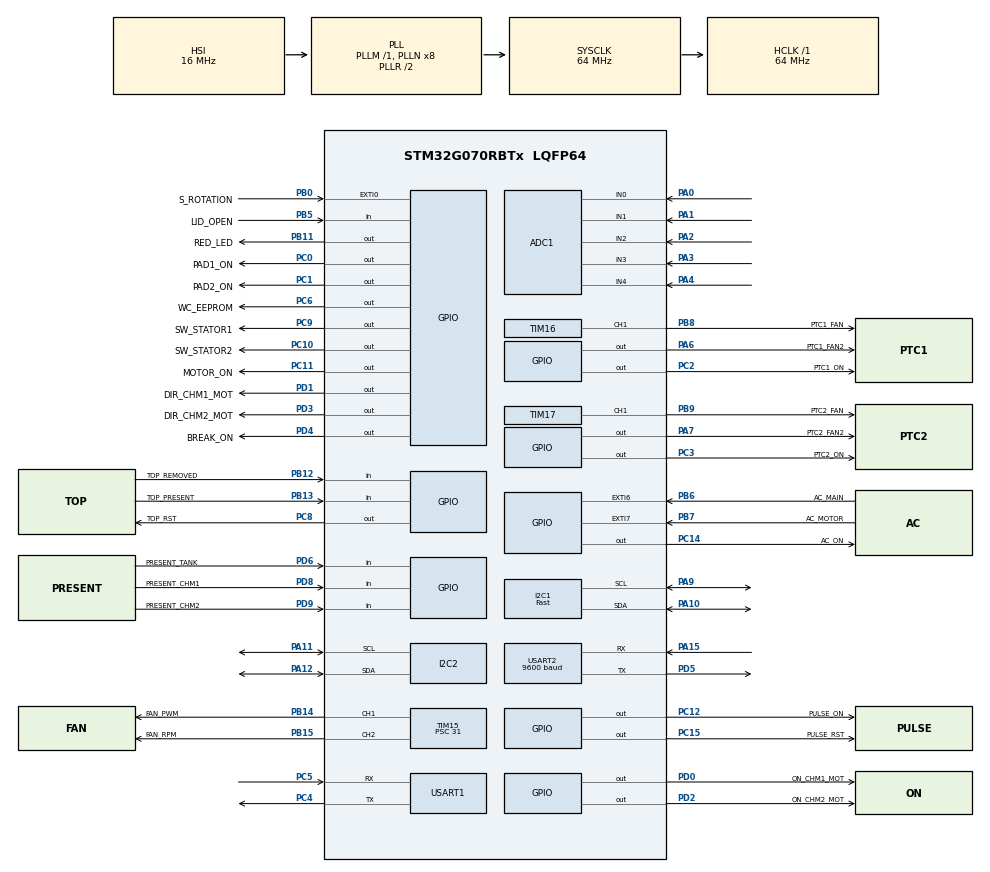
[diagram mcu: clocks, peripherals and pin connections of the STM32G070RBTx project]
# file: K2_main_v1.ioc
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ADC1.Channel-0\#ChannelRegularConversion=ADC_CHANNEL_0
ADC1.Channel-1\#ChannelRegularConversion=ADC_CHANNEL_1
ADC1.Channel-2\#ChannelRegularConversion=ADC_CHANNEL_2
ADC1.Channel-3\#ChannelRegularConversion=ADC_CHANNEL_3
ADC1.Channel-4\#ChannelRegularConversion=ADC_CHANNEL_4
ADC1.Channel-5\#ChannelRegularConversion=ADC_CHANNEL_TEMPSENSOR
ADC1.Channel-6\#ChannelRegularConversion=ADC_CHANNEL_VREFINT
ADC1.Channel-7\#ChannelRegularConversion=ADC_CHANNEL_VBAT
ADC1.EOCSelection=ADC_EOC_SEQ_CONV
ADC1.NbrOfConversion=8
ADC1.NbrOfConversionFlag=1
ADC1.Rank-0\#ChannelRegularConversion=1
ADC1.Rank-1\#ChannelRegularConversion=2
ADC1.Rank-2\#ChannelRegularConversion=3
ADC1.Rank-3\#ChannelRegularConversion=4
ADC1.Rank-4\#ChannelRegularConversion=5
ADC1.Rank-5\#ChannelRegularConversion=6
ADC1.Rank-6\#ChannelRegularConversion=7
ADC1.Rank-7\#ChannelRegularConversion=8
ADC1.SamplingTime-0\#ChannelRegularConversion=ADC_SAMPLINGTIME_COMMON_1
ADC1.SamplingTime-1\#ChannelRegularConversion=ADC_SAMPLINGTIME_COMMON_1
ADC1.SamplingTime-2\#ChannelRegularConversion=ADC_SAMPLINGTIME_COMMON_1
ADC1.SamplingTime-3\#ChannelRegularConversion=ADC_SAMPLINGTIME_COMMON_1
ADC1.SamplingTime-4\#ChannelRegularConversion=ADC_SAMPLINGTIME_COMMON_1
ADC1.SamplingTime-5\#ChannelRegularConversion=ADC_SAMPLINGTIME_COMMON_1
ADC1.SamplingTime-6\#ChannelRegularConversion=ADC_SAMPLINGTIME_COMMON_1
ADC1.SamplingTime-7\#ChannelRegularConversion=ADC_SAMPLINGTIME_COMMON_1
ADC1.SamplingTimeCommon1=ADC_SAMPLETIME_3CYCLES_5
ADC1.SelectedChannel=ADC_CHANNEL_0|ADC_CHANNEL_1|ADC_CHANNEL_2|ADC_CHANNEL_3|ADC_CHANNEL_4|ADC_CHANNEL_TEMPSENSOR|ADC_CHANNEL_VREFINT|ADC_CHANNEL_VBAT
ADC1.master=1
Dma.ADC1.0.Direction=DMA_PERIPH_TO_MEMORY
Dma.ADC1.0.EventEnable=DISABLE
Dma.ADC1.0.Instance=DMA1_Channel1
Dma.ADC1.0.MemDataAlignment=DMA_MDATAALIGN_HALFWORD
Dma.ADC1.0.MemInc=DMA_MINC_ENABLE
Dma.ADC1.0.Mode=DMA_NORMAL
Dma.ADC1.0.PeriphDataAlignment=DMA_PDATAALIGN_HALFWORD
Dma.ADC1.0.PeriphInc=DMA_PINC_DISABLE
Dma.ADC1.0.Polarity=HAL_DMAMUX_REQ_GEN_RISING
Dma.ADC1.0.Priority=DMA_PRIORITY_LOW
Dma.ADC1.0.RequestNumber=1
Dma.ADC1.0.SignalID=NONE
Dma.ADC1.0.SyncEnable=DISABLE
Dma.ADC1.0.SyncPolarity=HAL_DMAMUX_SYNC_NO_EVENT
Dma.ADC1.0.SyncRequestNumber=1
Dma.ADC1.0.SyncSignalID=NONE
Dma.Request0=ADC1
Dma.Request1=USART1_RX
Dma.Request2=USART1_TX
Dma.Request3=USART2_RX
Dma.Request4=USART2_TX
Dma.USART1_RX.1.Direction=DMA_PERIPH_TO_MEMORY
Dma.USART1_RX.1.EventEnable=DISABLE
Dma.USART1_RX.1.Instance=DMA1_Channel2
Dma.USART1_RX.1.MemDataAlignment=DMA_MDATAALIGN_BYTE
Dma.USART1_RX.1.MemInc=DMA_MINC_ENABLE
Dma.USART1_RX.1.Mode=DMA_NORMAL
Dma.USART1_RX.1.PeriphDataAlignment=DMA_PDATAALIGN_BYTE
Dma.USART1_RX.1.PeriphInc=DMA_PINC_DISABLE
Dma.USART1_RX.1.Polarity=HAL_DMAMUX_REQ_GEN_RISING
Dma.USART1_RX.1.Priority=DMA_PRIORITY_LOW
Dma.USART1_RX.1.RequestNumber=1
Dma.USART1_RX.1.SignalID=NONE
Dma.USART1_RX.1.SyncEnable=DISABLE
Dma.USART1_RX.1.SyncPolarity=HAL_DMAMUX_SYNC_NO_EVENT
Dma.USART1_RX.1.SyncRequestNumber=1
Dma.USART1_RX.1.SyncSignalID=NONE
Dma.USART1_TX.2.Direction=DMA_MEMORY_TO_PERIPH
Dma.USART1_TX.2.EventEnable=DISABLE
Dma.USART1_TX.2.Instance=DMA1_Channel3
Dma.USART1_TX.2.MemDataAlignment=DMA_MDATAALIGN_BYTE
Dma.USART1_TX.2.MemInc=DMA_MINC_ENABLE
Dma.USART1_TX.2.Mode=DMA_NORMAL
Dma.USART1_TX.2.PeriphDataAlignment=DMA_PDATAALIGN_BYTE
Dma.USART1_TX.2.PeriphInc=DMA_PINC_DISABLE
Dma.USART1_TX.2.Polarity=HAL_DMAMUX_REQ_GEN_RISING
Dma.USART1_TX.2.Priority=DMA_PRIORITY_LOW
Dma.USART1_TX.2.RequestNumber=1
Dma.USART1_TX.2.SignalID=NONE
Dma.USART1_TX.2.SyncEnable=DISABLE
Dma.USART1_TX.2.SyncPolarity=HAL_DMAMUX_SYNC_NO_EVENT
Dma.USART1_TX.2.SyncRequestNumber=1
Dma.USART1_TX.2.SyncSignalID=NONE
Dma.USART2_RX.3.Direction=DMA_PERIPH_TO_MEMORY
Dma.USART2_RX.3.EventEnable=DISABLE
Dma.USART2_RX.3.Instance=DMA1_Channel4
Dma.USART2_RX.3.MemDataAlignment=DMA_MDATAALIGN_BYTE
Dma.USART2_RX.3.MemInc=DMA_MINC_ENABLE
Dma.USART2_RX.3.Mode=DMA_NORMAL
Dma.USART2_RX.3.PeriphDataAlignment=DMA_PDATAALIGN_BYTE
Dma.USART2_RX.3.PeriphInc=DMA_PINC_DISABLE
Dma.USART2_RX.3.Polarity=HAL_DMAMUX_REQ_GEN_RISING
Dma.USART2_RX.3.Priority=DMA_PRIORITY_LOW
Dma.USART2_RX.3.RequestNumber=1
Dma.USART2_RX.3.SignalID=NONE
Dma.USART2_RX.3.SyncEnable=DISABLE
Dma.USART2_RX.3.SyncPolarity=HAL_DMAMUX_SYNC_NO_EVENT
Dma.USART2_RX.3.SyncRequestNumber=1
Dma.USART2_RX.3.SyncSignalID=NONE
Dma.USART2_TX.4.Direction=DMA_MEMORY_TO_PERIPH
Dma.USART2_TX.4.EventEnable=DISABLE
Dma.USART2_TX.4.Instance=DMA1_Channel5
Dma.USART2_TX.4.MemDataAlignment=DMA_MDATAALIGN_BYTE
Dma.USART2_TX.4.MemInc=DMA_MINC_ENABLE
Dma.USART2_TX.4.Mode=DMA_NORMAL
Dma.USART2_TX.4.PeriphDataAlignment=DMA_PDATAALIGN_BYTE
Dma.USART2_TX.4.PeriphInc=DMA_PINC_DISABLE
Dma.USART2_TX.4.Polarity=HAL_DMAMUX_REQ_GEN_RISING
Dma.USART2_TX.4.Priority=DMA_PRIORITY_LOW
Dma.USART2_TX.4.RequestNumber=1
Dma.USART2_TX.4.SignalID=NONE
Dma.USART2_TX.4.SyncEnable=DISABLE
Dma.USART2_TX.4.SyncPolarity=HAL_DMAMUX_SYNC_NO_EVENT
Dma.USART2_TX.4.SyncRequestNumber=1
Dma.USART2_TX.4.SyncSignalID=NONE
FREERTOS.INCLUDE_xEventGroupSetBitFromISR=1
FREERTOS.INCLUDE_xTimerPendFunctionCall=1
FREERTOS.MEMORY_ALLOCATION=2
FREERTOS.Tasks01=defaultTask,0,64,StartDefaultTask,Default,NULL,Static,defaultTaskBuffer,defaultTaskControlBlock
FREERTOS.configMAX_PRIORITIES=10
FREERTOS.configMAX_TASK_NAME_LEN=32
FREERTOS.configMINIMAL_STACK_SIZE=64
FREERTOS.configTOTAL_HEAP_SIZE=1024
FREERTOS.configUSE_NEWLIB_REENTRANT=1
FREERTOS.configUSE_TICK_HOOK=1
FREERTOS.configUSE_TIMERS=1
I2C1.I2C_Speed_Mode=I2C_Fast
I2C1.Timing=0x00602173
I2C2.Timing=0x10707DBC
Mcu.Family=STM32G0
Mcu.Name=STM32G070RBTx
Mcu.Package=LQFP64
NVIC.DMA1_Ch4_7_DMAMUX1_OVR_IRQn=true\:3\:0\:false\:false\:true\:true\:false\:true\:true
NVIC.DMA1_Channel1_IRQn=true\:3\:0\:false\:false\:true\:true\:false\:true\:true
NVIC.DMA1_Channel2_3_IRQn=true\:3\:0\:false\:false\:true\:true\:false\:true\:true
NVIC.EXTI4_15_IRQn=true\:3\:0\:false\:false\:true\:true\:true\:true\:true
NVIC.USART1_IRQn=true\:3\:0\:false\:false\:true\:true\:true\:true\:true
NVIC.USART2_IRQn=true\:3\:0\:false\:false\:true\:true\:true\:true\:true
PA0.Mode=IN0
PA0.Signal=ADC1_IN0
PA1.Mode=IN1
PA1.Signal=ADC1_IN1
PA10.Mode=I2C
PA10.Signal=I2C1_SDA
PA11\ [PA9].Mode=I2C
PA11\ [PA9].Signal=I2C2_SCL
PA12\ [PA10].Mode=I2C
PA12\ [PA10].Signal=I2C2_SDA
PA13.Mode=Serial_Wire
PA13.Signal=SYS_SWDIO
PA14-BOOT0.Mode=Serial_Wire
PA14-BOOT0.Signal=SYS_SWCLK
PA15.GPIO_PuPd=GPIO_NOPULL
PA15.Mode=Asynchronous
PA15.Signal=USART2_RX
PA2.Mode=IN2
PA2.Signal=ADC1_IN2
PA3.Mode=IN3
PA3.Signal=ADC1_IN3
PA4.Mode=IN4
PA4.Signal=ADC1_IN4
PA6.GPIO_Label=PTC1_FAN2
PA6.GPIO_ModeDefaultOutputPP=GPIO_MODE_OUTPUT_OD
PA6.GPIO_PuPd=GPIO_NOPULL
PA6.PinState=GPIO_PIN_SET
PA6.Signal=GPIO_Output
PA7.GPIO_Label=PTC2_FAN2
PA7.GPIO_ModeDefaultOutputPP=GPIO_MODE_OUTPUT_OD
PA7.GPIO_PuPd=GPIO_NOPULL
PA7.PinState=GPIO_PIN_SET
PA7.Signal=GPIO_Output
PA9.Mode=I2C
PA9.Signal=I2C1_SCL
PB0.GPIO_Label=S_ROTATION
PB0.Signal=GPXTI0
PB11.GPIO_Label=RED_LED
PB11.GPIO_ModeDefaultOutputPP=GPIO_MODE_OUTPUT_OD
PB11.GPIO_PuPd=GPIO_NOPULL
PB11.PinState=GPIO_PIN_SET
PB11.Signal=GPIO_Output
PB12.GPIO_Label=TOP_REMOVED
PB12.Signal=GPIO_Input
PB13.GPIO_Label=TOP_PRESENT
PB13.Signal=GPIO_Input
PB14.GPIO_Label=FAN_PWM
PB14.Signal=S_TIM15_CH1
PB15.GPIO_Label=FAN_RPM
PB15.Signal=S_TIM15_CH2
PB5.GPIO_Label=LID_OPEN
PB5.Signal=GPIO_Input
PB6.GPIO_Label=AC_MAIN
PB6.GPIO_ModeDefaultEXTI=GPIO_MODE_IT_FALLING
PB6.Signal=GPXTI6
PB7.GPIO_Label=AC_MOTOR
PB7.GPIO_ModeDefaultEXTI=GPIO_MODE_IT_FALLING
PB7.Signal=GPXTI7
PB8.GPIO_Label=PTC1_FAN
PB8.Signal=S_TIM16_CH1
PB9.GPIO_Label=PTC2_FAN
PB9.Signal=S_TIM17_CH1
PC0.GPIO_Label=PAD1_ON
PC0.GPIO_ModeDefaultOutputPP=GPIO_MODE_OUTPUT_OD
PC0.GPIO_PuPd=GPIO_NOPULL
PC0.PinState=GPIO_PIN_SET
PC0.Signal=GPIO_Output
PC1.GPIO_Label=PAD2_ON
PC1.GPIO_ModeDefaultOutputPP=GPIO_MODE_OUTPUT_OD
PC1.GPIO_PuPd=GPIO_NOPULL
PC1.PinState=GPIO_PIN_SET
PC1.Signal=GPIO_Output
PC10.GPIO_Label=SW_STATOR2
PC10.Signal=GPIO_Output
PC11.GPIO_Label=MOTOR_ON
PC11.GPIO_ModeDefaultOutputPP=GPIO_MODE_OUTPUT_OD
PC11.GPIO_PuPd=GPIO_PULLUP
PC11.Signal=GPIO_Output
PC12.GPIO_Label=PULSE_ON
PC12.GPIO_ModeDefaultOutputPP=GPIO_MODE_OUTPUT_OD
PC12.GPIO_PuPd=GPIO_NOPULL
PC12.PinState=GPIO_PIN_SET
PC12.Signal=GPIO_Output
PC13.Mode=SYS_WakeUp1
PC13.Signal=SYS_WKUP2
PC14-OSC32_IN\ (PC14).GPIO_Label=AC_ON
PC14-OSC32_IN\ (PC14).Signal=GPIO_Output
PC15-OSC32_OUT\ (PC15).GPIO_Label=PULSE_RST
PC15-OSC32_OUT\ (PC15).Signal=GPIO_Output
PC2.GPIO_Label=PTC1_ON
PC2.GPIO_ModeDefaultOutputPP=GPIO_MODE_OUTPUT_OD
PC2.GPIO_PuPd=GPIO_NOPULL
PC2.PinState=GPIO_PIN_SET
PC2.Signal=GPIO_Output
PC3.GPIO_Label=PTC2_ON
PC3.GPIO_ModeDefaultOutputPP=GPIO_MODE_OUTPUT_OD
PC3.GPIO_PuPd=GPIO_NOPULL
PC3.PinState=GPIO_PIN_SET
PC3.Signal=GPIO_Output
PC4.GPIO_PuPd=GPIO_PULLUP
PC4.Mode=Asynchronous
PC4.Signal=USART1_TX
PC5.GPIO_PuPd=GPIO_PULLUP
PC5.Mode=Asynchronous
PC5.Signal=USART1_RX
PC6.GPIO_Label=WC_EEPROM
PC6.GPIO_PuPd=GPIO_NOPULL
PC6.PinState=GPIO_PIN_SET
PC6.Signal=GPIO_Output
PC8.GPIO_Label=TOP_RST
PC8.Signal=GPIO_Output
PC9.GPIO_Label=SW_STATOR1
PC9.Signal=GPIO_Output
PD0.GPIO_Label=ON_CHM1_MOT
PD0.Signal=GPIO_Output
PD1.GPIO_Label=DIR_CHM1_MOT
PD1.Signal=GPIO_Output
PD2.GPIO_Label=ON_CHM2_MOT
PD2.Signal=GPIO_Output
PD3.GPIO_Label=DIR_CHM2_MOT
PD3.Signal=GPIO_Output
PD4.GPIO_Label=BREAK_ON
PD4.Signal=GPIO_Output
PD5.Mode=Asynchronous
PD5.Signal=USART2_TX
PD6.GPIO_Label=PRESENT_TANK
PD6.Signal=GPIO_Input
PD8.GPIO_Label=PRESENT_CHM1
PD8.Signal=GPIO_Input
PD9.GPIO_Label=PRESENT_CHM2
PD9.Signal=GPIO_Input
ProjectManager.HeapSize=0x200
ProjectManager.StackSize=0x400
ProjectManager.TargetToolchain=STM32CubeIDE
RCC.ADCFreq_Value=64000000
RCC.AHBFreq_Value=64000000
RCC.CortexFreq_Value=64000000
RCC.EXTERNAL_CLOCK_VALUE=48000
RCC.HCLKFreq_Value=64000000
RCC.HSE_VALUE=8000000
RCC.HSI_VALUE=16000000
RCC.LSE_VALUE=32768
RCC.SYSCLKFreq_VALUE=64000000
RCC.SYSCLKSource=RCC_SYSCLKSOURCE_PLLCLK
RCC.VCOOutputFreq_Value=128000000
SH.S_TIM15_CH1.0=TIM15_CH1,PWM Generation1 CH1
SH.S_TIM15_CH2.0=TIM15_CH2,PWM Generation2 CH2
SH.S_TIM16_CH1.0=TIM16_CH1,PWM Generation1 CH1
SH.S_TIM17_CH1.0=TIM17_CH1,PWM Generation1 CH1
TIM15.AutoReloadPreload=TIM_AUTORELOAD_PRELOAD_ENABLE
TIM15.Channel-PWM\ Generation1\ CH1=TIM_CHANNEL_1
TIM15.Channel-PWM\ Generation2\ CH2=TIM_CHANNEL_2
TIM15.Period=99
TIM15.Prescaler=31
TIM16.AutoReloadPreload=TIM_AUTORELOAD_PRELOAD_ENABLE
TIM16.Channel=TIM_CHANNEL_1
TIM16.OCIdleState_1=TIM_OCIDLESTATE_RESET
TIM16.OCPolarity_1=TIM_OCPOLARITY_HIGH
TIM16.Period=99
TIM16.Prescaler=31
TIM17.AutoReloadPreload=TIM_AUTORELOAD_PRELOAD_ENABLE
TIM17.Channel=TIM_CHANNEL_1
TIM17.Period=99
TIM17.Prescaler=31
USART1.VirtualMode-Asynchronous=VM_ASYNC
USART2.BaudRate=9600
USART2.TxPinLevelInvertParam=ADVFEATURE_TXINV_ENABLE
USART2.VirtualMode-Asynchronous=VM_ASYNC
VP_ADC1_TempSens_Input.Mode=IN-TempSens
VP_ADC1_Vbat_Input.Mode=IN-Vbat
VP_ADC1_Vref_Input.Mode=IN-Vrefint
VP_FREERTOS_VS_CMSIS_V1.Mode=CMSIS_V1
VP_TIM15_VS_ClockSourceINT.Mode=Internal
VP_TIM16_VS_ClockSourceINT.Mode=Enable_Timer
VP_TIM17_VS_ClockSourceINT.Mode=Enable_Timer
board=custom

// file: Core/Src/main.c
/* USER CODE BEGIN Header */
/**
  ******************************************************************************
  * @file           : main.c
  * @brief          : Main program body
  ******************************************************************************
  * @attention
  *
  * Copyright (c) 2023 STMicroelectronics.
  * All rights reserved.
  *
  * This software is licensed under terms that can be found in the LICENSE file
  * in the root directory of this software component.
  * If no LICENSE file comes with this software, it is provided AS-IS.
  *
  ******************************************************************************
  */
/* USER CODE END Header */
#include "main.h"
#include "cmsis_os.h"

/* USER CODE BEGIN Includes */
#include "ConfigApplication.h"
/* USER CODE END Includes */

ADC_HandleTypeDef hadc1;
DMA_HandleTypeDef hdma_adc1;

I2C_HandleTypeDef hi2c1;
I2C_HandleTypeDef hi2c2;

TIM_HandleTypeDef htim15;
TIM_HandleTypeDef htim16;
TIM_HandleTypeDef htim17;

UART_HandleTypeDef huart1;
UART_HandleTypeDef huart2;
DMA_HandleTypeDef hdma_usart1_rx;
DMA_HandleTypeDef hdma_usart1_tx;
DMA_HandleTypeDef hdma_usart2_rx;
DMA_HandleTypeDef hdma_usart2_tx;

/* osThreadId defaultTaskHandle;
uint32_t defaultTaskBuffer[ 64 ];
osStaticThreadDef_t defaultTaskControlBlock; */

void SystemClock_Config(void);
static void MX_GPIO_Init(void);
static void MX_DMA_Init(void);
static void MX_ADC1_Init(void);
static void MX_I2C1_Init(void);
static void MX_USART1_UART_Init(void);
static void MX_USART2_UART_Init(void);
static void MX_TIM16_Init(void);
static void MX_TIM15_Init(void);
static void MX_I2C2_Init(void);
static void MX_TIM17_Init(void);
// void StartDefaultTask(void const * argument);

/* USER CODE BEGIN PFP */
extern void CreateApplicationTasks(void);
/* USER CODE END PFP */

int main(void)
{

  /* MCU Configuration--------------------------------------------------------*/

  /* Reset of all peripherals, Initializes the Flash interface and the Systick. */
  HAL_Init();

  /* Configure the system clock */
  SystemClock_Config();

  /* Initialize all configured peripherals */
  MX_GPIO_Init();
  MX_DMA_Init();
  MX_ADC1_Init();
  MX_I2C1_Init();
  MX_USART1_UART_Init();
  MX_USART2_UART_Init();
  MX_TIM16_Init();
  MX_TIM15_Init();
  MX_I2C2_Init();
  MX_TIM17_Init();

  /* Create the thread(s) */
  /* definition and creation of defaultTask */
  // osThreadStaticDef(defaultTask, StartDefaultTask, osPriorityNormal, 0, 64, defaultTaskBuffer, &defaultTaskControlBlock);
  // defaultTaskHandle = osThreadCreate(osThread(defaultTask), NULL);

  /* USER CODE BEGIN RTOS_THREADS */
  /* add threads, ... */
  CreateApplicationTasks();
  /* USER CODE END RTOS_THREADS */

  /* Start scheduler */
  osKernelStart();
  /* We should never get here as control is now taken by the scheduler */
  /* Infinite loop */
  while (1)
  {

  }
}

void SystemClock_Config(void)
{
  RCC_OscInitTypeDef RCC_OscInitStruct = {0};
  RCC_ClkInitTypeDef RCC_ClkInitStruct = {0};

  /** Configure the main internal regulator output voltage
  */
  HAL_PWREx_ControlVoltageScaling(PWR_REGULATOR_VOLTAGE_SCALE1);

  /** Initializes the RCC Oscillators according to the specified parameters
  * in the RCC_OscInitTypeDef structure.
  */
  RCC_OscInitStruct.OscillatorType = RCC_OSCILLATORTYPE_HSI;
  RCC_OscInitStruct.HSIState = RCC_HSI_ON;
  RCC_OscInitStruct.HSIDiv = RCC_HSI_DIV1;
  RCC_OscInitStruct.HSICalibrationValue = RCC_HSICALIBRATION_DEFAULT;
  RCC_OscInitStruct.PLL.PLLState = RCC_PLL_ON;
  RCC_OscInitStruct.PLL.PLLSource = RCC_PLLSOURCE_HSI;
  RCC_OscInitStruct.PLL.PLLM = RCC_PLLM_DIV1;
  RCC_OscInitStruct.PLL.PLLN = 8;
  RCC_OscInitStruct.PLL.PLLP = RCC_PLLP_DIV2;
  RCC_OscInitStruct.PLL.PLLR = RCC_PLLR_DIV2;
  if (HAL_RCC_OscConfig(&RCC_OscInitStruct) != HAL_OK)
  {
    Error_Handler();
  }

  /** Initializes the CPU, AHB and APB buses clocks
  */
  RCC_ClkInitStruct.ClockType = RCC_CLOCKTYPE_HCLK|RCC_CLOCKTYPE_SYSCLK
                              |RCC_CLOCKTYPE_PCLK1;
  RCC_ClkInitStruct.SYSCLKSource = RCC_SYSCLKSOURCE_PLLCLK;
  RCC_ClkInitStruct.AHBCLKDivider = RCC_SYSCLK_DIV1;
  RCC_ClkInitStruct.APB1CLKDivider = RCC_HCLK_DIV1;

  if (HAL_RCC_ClockConfig(&RCC_ClkInitStruct, FLASH_LATENCY_2) != HAL_OK)
  {
    Error_Handler();
  }
}

static void MX_ADC1_Init(void)
{

  ADC_ChannelConfTypeDef sConfig = {0};

  /** Configure the global features of the ADC (Clock, Resolution, Data Alignment and number of conversion)
  */
  hadc1.Instance = ADC1;
  hadc1.Init.ClockPrescaler = ADC_CLOCK_SYNC_PCLK_DIV2;
  hadc1.Init.Resolution = ADC_RESOLUTION_12B;
  hadc1.Init.DataAlign = ADC_DATAALIGN_RIGHT;
  hadc1.Init.ScanConvMode = ADC_SCAN_ENABLE;
  hadc1.Init.EOCSelection = ADC_EOC_SEQ_CONV;
  hadc1.Init.LowPowerAutoWait = DISABLE;
  hadc1.Init.LowPowerAutoPowerOff = DISABLE;
  hadc1.Init.ContinuousConvMode = DISABLE;
  hadc1.Init.NbrOfConversion = 8;
  hadc1.Init.DiscontinuousConvMode = DISABLE;
  hadc1.Init.ExternalTrigConv = ADC_SOFTWARE_START;
  hadc1.Init.ExternalTrigConvEdge = ADC_EXTERNALTRIGCONVEDGE_NONE;
  hadc1.Init.DMAContinuousRequests = DISABLE;
  hadc1.Init.Overrun = ADC_OVR_DATA_PRESERVED;
  hadc1.Init.SamplingTimeCommon1 = ADC_SAMPLETIME_3CYCLES_5;
  hadc1.Init.SamplingTimeCommon2 = ADC_SAMPLETIME_1CYCLE_5;
  hadc1.Init.OversamplingMode = DISABLE;
  hadc1.Init.TriggerFrequencyMode = ADC_TRIGGER_FREQ_HIGH;
  if (HAL_ADC_Init(&hadc1) != HAL_OK)
  {
    Error_Handler();
  }

  /** Configure Regular Channel
  */
  sConfig.Channel = ADC_CHANNEL_0;
  sConfig.Rank = ADC_REGULAR_RANK_1;
  sConfig.SamplingTime = ADC_SAMPLINGTIME_COMMON_1;
  if (HAL_ADC_ConfigChannel(&hadc1, &sConfig) != HAL_OK)
  {
    Error_Handler();
  }

  /** Configure Regular Channel
  */
  sConfig.Channel = ADC_CHANNEL_1;
  sConfig.Rank = ADC_REGULAR_RANK_2;
  if (HAL_ADC_ConfigChannel(&hadc1, &sConfig) != HAL_OK)
  {
    Error_Handler();
  }

  /** Configure Regular Channel
  */
  sConfig.Channel = ADC_CHANNEL_2;
  sConfig.Rank = ADC_REGULAR_RANK_3;
  if (HAL_ADC_ConfigChannel(&hadc1, &sConfig) != HAL_OK)
  {
    Error_Handler();
  }

  /** Configure Regular Channel
  */
  sConfig.Channel = ADC_CHANNEL_3;
  sConfig.Rank = ADC_REGULAR_RANK_4;
  if (HAL_ADC_ConfigChannel(&hadc1, &sConfig) != HAL_OK)
  {
    Error_Handler();
  }

  /** Configure Regular Channel
  */
  sConfig.Channel = ADC_CHANNEL_4;
  sConfig.Rank = ADC_REGULAR_RANK_5;
  if (HAL_ADC_ConfigChannel(&hadc1, &sConfig) != HAL_OK)
  {
    Error_Handler();
  }

  /** Configure Regular Channel
  */
  sConfig.Channel = ADC_CHANNEL_TEMPSENSOR;
  sConfig.Rank = ADC_REGULAR_RANK_6;
  if (HAL_ADC_ConfigChannel(&hadc1, &sConfig) != HAL_OK)
  {
    Error_Handler();
  }

  /** Configure Regular Channel
  */
  sConfig.Channel = ADC_CHANNEL_VREFINT;
  sConfig.Rank = ADC_REGULAR_RANK_7;
  if (HAL_ADC_ConfigChannel(&hadc1, &sConfig) != HAL_OK)
  {
    Error_Handler();
  }

  /** Configure Regular Channel
  */
  sConfig.Channel = ADC_CHANNEL_VBAT;
  sConfig.Rank = ADC_REGULAR_RANK_8;
  if (HAL_ADC_ConfigChannel(&hadc1, &sConfig) != HAL_OK)
  {
    Error_Handler();
  }

}

static void MX_I2C1_Init(void)
{

  hi2c1.Instance = I2C1;
  hi2c1.Init.Timing = 0x00602173;
  hi2c1.Init.OwnAddress1 = 0;
  hi2c1.Init.AddressingMode = I2C_ADDRESSINGMODE_7BIT;
  hi2c1.Init.DualAddressMode = I2C_DUALADDRESS_DISABLE;
  hi2c1.Init.OwnAddress2 = 0;
  hi2c1.Init.OwnAddress2Masks = I2C_OA2_NOMASK;
  hi2c1.Init.GeneralCallMode = I2C_GENERALCALL_DISABLE;
  hi2c1.Init.NoStretchMode = I2C_NOSTRETCH_DISABLE;
  if (HAL_I2C_Init(&hi2c1) != HAL_OK)
  {
    Error_Handler();
  }

  /** Configure Analogue filter
  */
  if (HAL_I2CEx_ConfigAnalogFilter(&hi2c1, I2C_ANALOGFILTER_ENABLE) != HAL_OK)
  {
    Error_Handler();
  }

  /** Configure Digital filter
  */
  if (HAL_I2CEx_ConfigDigitalFilter(&hi2c1, 0) != HAL_OK)
  {
    Error_Handler();
  }

}

static void MX_I2C2_Init(void)
{

  hi2c2.Instance = I2C2;
  hi2c2.Init.Timing = 0x10707DBC;
  hi2c2.Init.OwnAddress1 = 0;
  hi2c2.Init.AddressingMode = I2C_ADDRESSINGMODE_7BIT;
  hi2c2.Init.DualAddressMode = I2C_DUALADDRESS_DISABLE;
  hi2c2.Init.OwnAddress2 = 0;
  hi2c2.Init.OwnAddress2Masks = I2C_OA2_NOMASK;
  hi2c2.Init.GeneralCallMode = I2C_GENERALCALL_DISABLE;
  hi2c2.Init.NoStretchMode = I2C_NOSTRETCH_DISABLE;
  if (HAL_I2C_Init(&hi2c2) != HAL_OK)
  {
    Error_Handler();
  }

  /** Configure Analogue filter
  */
  if (HAL_I2CEx_ConfigAnalogFilter(&hi2c2, I2C_ANALOGFILTER_ENABLE) != HAL_OK)
  {
    Error_Handler();
  }

  /** Configure Digital filter
  */
  if (HAL_I2CEx_ConfigDigitalFilter(&hi2c2, 0) != HAL_OK)
  {
    Error_Handler();
  }

}

static void MX_TIM15_Init(void)
{

  TIM_ClockConfigTypeDef sClockSourceConfig = {0};
  TIM_MasterConfigTypeDef sMasterConfig = {0};
  TIM_OC_InitTypeDef sConfigOC = {0};
  TIM_BreakDeadTimeConfigTypeDef sBreakDeadTimeConfig = {0};

  htim15.Instance = TIM15;
  htim15.Init.Prescaler = 31;
  htim15.Init.CounterMode = TIM_COUNTERMODE_UP;
  htim15.Init.Period = 99;
  htim15.Init.ClockDivision = TIM_CLOCKDIVISION_DIV1;
  htim15.Init.RepetitionCounter = 0;
  htim15.Init.AutoReloadPreload = TIM_AUTORELOAD_PRELOAD_ENABLE;
  if (HAL_TIM_Base_Init(&htim15) != HAL_OK)
  {
    Error_Handler();
  }
  sClockSourceConfig.ClockSource = TIM_CLOCKSOURCE_INTERNAL;
  if (HAL_TIM_ConfigClockSource(&htim15, &sClockSourceConfig) != HAL_OK)
  {
    Error_Handler();
  }
  if (HAL_TIM_PWM_Init(&htim15) != HAL_OK)
  {
    Error_Handler();
  }
  sMasterConfig.MasterOutputTrigger = TIM_TRGO_RESET;
  sMasterConfig.MasterSlaveMode = TIM_MASTERSLAVEMODE_DISABLE;
  if (HAL_TIMEx_MasterConfigSynchronization(&htim15, &sMasterConfig) != HAL_OK)
  {
    Error_Handler();
  }
  sConfigOC.OCMode = TIM_OCMODE_PWM1;
  sConfigOC.Pulse = 0;
  sConfigOC.OCPolarity = TIM_OCPOLARITY_HIGH;
  sConfigOC.OCNPolarity = TIM_OCNPOLARITY_HIGH;
  sConfigOC.OCFastMode = TIM_OCFAST_DISABLE;
  sConfigOC.OCIdleState = TIM_OCIDLESTATE_RESET;
  sConfigOC.OCNIdleState = TIM_OCNIDLESTATE_RESET;
  if (HAL_TIM_PWM_ConfigChannel(&htim15, &sConfigOC, TIM_CHANNEL_1) != HAL_OK)
  {
    Error_Handler();
  }
  if (HAL_TIM_PWM_ConfigChannel(&htim15, &sConfigOC, TIM_CHANNEL_2) != HAL_OK)
  {
    Error_Handler();
  }
  sBreakDeadTimeConfig.OffStateRunMode = TIM_OSSR_DISABLE;
  sBreakDeadTimeConfig.OffStateIDLEMode = TIM_OSSI_DISABLE;
  sBreakDeadTimeConfig.LockLevel = TIM_LOCKLEVEL_OFF;
  sBreakDeadTimeConfig.DeadTime = 0;
  sBreakDeadTimeConfig.BreakState = TIM_BREAK_DISABLE;
  sBreakDeadTimeConfig.BreakPolarity = TIM_BREAKPOLARITY_HIGH;
  sBreakDeadTimeConfig.BreakFilter = 0;
  sBreakDeadTimeConfig.AutomaticOutput = TIM_AUTOMATICOUTPUT_DISABLE;
  if (HAL_TIMEx_ConfigBreakDeadTime(&htim15, &sBreakDeadTimeConfig) != HAL_OK)
  {
    Error_Handler();
  }
  HAL_TIM_MspPostInit(&htim15);

}

static void MX_TIM16_Init(void)
{

  TIM_OC_InitTypeDef sConfigOC = {0};
  TIM_BreakDeadTimeConfigTypeDef sBreakDeadTimeConfig = {0};

  htim16.Instance = TIM16;
  htim16.Init.Prescaler = 31;
  htim16.Init.CounterMode = TIM_COUNTERMODE_UP;
  htim16.Init.Period = 99;
  htim16.Init.ClockDivision = TIM_CLOCKDIVISION_DIV1;
  htim16.Init.RepetitionCounter = 0;
  htim16.Init.AutoReloadPreload = TIM_AUTORELOAD_PRELOAD_ENABLE;
  if (HAL_TIM_Base_Init(&htim16) != HAL_OK)
  {
    Error_Handler();
  }
  if (HAL_TIM_PWM_Init(&htim16) != HAL_OK)
  {
    Error_Handler();
  }
  sConfigOC.OCMode = TIM_OCMODE_PWM1;
  sConfigOC.Pulse = 0;
  sConfigOC.OCPolarity = TIM_OCPOLARITY_HIGH;
  sConfigOC.OCNPolarity = TIM_OCNPOLARITY_HIGH;
  sConfigOC.OCFastMode = TIM_OCFAST_DISABLE;
  sConfigOC.OCIdleState = TIM_OCIDLESTATE_RESET;
  sConfigOC.OCNIdleState = TIM_OCNIDLESTATE_RESET;
  if (HAL_TIM_PWM_ConfigChannel(&htim16, &sConfigOC, TIM_CHANNEL_1) != HAL_OK)
  {
    Error_Handler();
  }
  sBreakDeadTimeConfig.OffStateRunMode = TIM_OSSR_DISABLE;
  sBreakDeadTimeConfig.OffStateIDLEMode = TIM_OSSI_DISABLE;
  sBreakDeadTimeConfig.LockLevel = TIM_LOCKLEVEL_OFF;
  sBreakDeadTimeConfig.DeadTime = 0;
  sBreakDeadTimeConfig.BreakState = TIM_BREAK_DISABLE;
  sBreakDeadTimeConfig.BreakPolarity = TIM_BREAKPOLARITY_HIGH;
  sBreakDeadTimeConfig.BreakFilter = 0;
  sBreakDeadTimeConfig.AutomaticOutput = TIM_AUTOMATICOUTPUT_DISABLE;
  if (HAL_TIMEx_ConfigBreakDeadTime(&htim16, &sBreakDeadTimeConfig) != HAL_OK)
  {
    Error_Handler();
  }
  HAL_TIM_MspPostInit(&htim16);

}

static void MX_TIM17_Init(void)
{

  TIM_OC_InitTypeDef sConfigOC = {0};
  TIM_BreakDeadTimeConfigTypeDef sBreakDeadTimeConfig = {0};

  htim17.Instance = TIM17;
  htim17.Init.Prescaler = 31;
  htim17.Init.CounterMode = TIM_COUNTERMODE_UP;
  htim17.Init.Period = 99;
  htim17.Init.ClockDivision = TIM_CLOCKDIVISION_DIV1;
  htim17.Init.RepetitionCounter = 0;
  htim17.Init.AutoReloadPreload = TIM_AUTORELOAD_PRELOAD_ENABLE;
  if (HAL_TIM_Base_Init(&htim17) != HAL_OK)
  {
    Error_Handler();
  }
  if (HAL_TIM_PWM_Init(&htim17) != HAL_OK)
  {
    Error_Handler();
  }
  sConfigOC.OCMode = TIM_OCMODE_PWM1;
  sConfigOC.Pulse = 0;
  sConfigOC.OCPolarity = TIM_OCPOLARITY_HIGH;
  sConfigOC.OCNPolarity = TIM_OCNPOLARITY_HIGH;
  sConfigOC.OCFastMode = TIM_OCFAST_DISABLE;
  sConfigOC.OCIdleState = TIM_OCIDLESTATE_RESET;
  sConfigOC.OCNIdleState = TIM_OCNIDLESTATE_RESET;
  if (HAL_TIM_PWM_ConfigChannel(&htim17, &sConfigOC, TIM_CHANNEL_1) != HAL_OK)
  {
    Error_Handler();
  }
  sBreakDeadTimeConfig.OffStateRunMode = TIM_OSSR_DISABLE;
  sBreakDeadTimeConfig.OffStateIDLEMode = TIM_OSSI_DISABLE;
  sBreakDeadTimeConfig.LockLevel = TIM_LOCKLEVEL_OFF;
  sBreakDeadTimeConfig.DeadTime = 0;
  sBreakDeadTimeConfig.BreakState = TIM_BREAK_DISABLE;
  sBreakDeadTimeConfig.BreakPolarity = TIM_BREAKPOLARITY_HIGH;
  sBreakDeadTimeConfig.BreakFilter = 0;
  sBreakDeadTimeConfig.AutomaticOutput = TIM_AUTOMATICOUTPUT_DISABLE;
  if (HAL_TIMEx_ConfigBreakDeadTime(&htim17, &sBreakDeadTimeConfig) != HAL_OK)
  {
    Error_Handler();
  }
  HAL_TIM_MspPostInit(&htim17);

}

static void MX_USART1_UART_Init(void)
{

  huart1.Instance = USART1;
  huart1.Init.BaudRate = 115200;
  huart1.Init.WordLength = UART_WORDLENGTH_8B;
  huart1.Init.StopBits = UART_STOPBITS_1;
  huart1.Init.Parity = UART_PARITY_NONE;
  huart1.Init.Mode = UART_MODE_TX_RX;
  huart1.Init.HwFlowCtl = UART_HWCONTROL_NONE;
  huart1.Init.OverSampling = UART_OVERSAMPLING_16;
  huart1.Init.OneBitSampling = UART_ONE_BIT_SAMPLE_DISABLE;
  huart1.Init.ClockPrescaler = UART_PRESCALER_DIV1;
  huart1.AdvancedInit.AdvFeatureInit = UART_ADVFEATURE_NO_INIT;
  if (HAL_UART_Init(&huart1) != HAL_OK)
  {
    Error_Handler();
  }
  if (HAL_UARTEx_SetTxFifoThreshold(&huart1, UART_TXFIFO_THRESHOLD_1_8) != HAL_OK)
  {
    Error_Handler();
  }
  if (HAL_UARTEx_SetRxFifoThreshold(&huart1, UART_RXFIFO_THRESHOLD_1_8) != HAL_OK)
  {
    Error_Handler();
  }
  if (HAL_UARTEx_DisableFifoMode(&huart1) != HAL_OK)
  {
    Error_Handler();
  }

}

static void MX_USART2_UART_Init(void)
{

  huart2.Instance = USART2;
  huart2.Init.BaudRate = 9600;
  huart2.Init.WordLength = UART_WORDLENGTH_8B;
  huart2.Init.StopBits = UART_STOPBITS_1;
  huart2.Init.Parity = UART_PARITY_NONE;
  huart2.Init.Mode = UART_MODE_TX_RX;
  huart2.Init.HwFlowCtl = UART_HWCONTROL_NONE;
  huart2.Init.OverSampling = UART_OVERSAMPLING_16;
  huart2.Init.OneBitSampling = UART_ONE_BIT_SAMPLE_DISABLE;
  huart2.Init.ClockPrescaler = UART_PRESCALER_DIV1;
  huart2.AdvancedInit.AdvFeatureInit = UART_ADVFEATURE_TXINVERT_INIT;
  huart2.AdvancedInit.TxPinLevelInvert = UART_ADVFEATURE_TXINV_ENABLE;
  if (HAL_UART_Init(&huart2) != HAL_OK)
  {
    Error_Handler();
  }
  if (HAL_UARTEx_SetTxFifoThreshold(&huart2, UART_TXFIFO_THRESHOLD_1_8) != HAL_OK)
  {
    Error_Handler();
  }
  if (HAL_UARTEx_SetRxFifoThreshold(&huart2, UART_RXFIFO_THRESHOLD_1_8) != HAL_OK)
  {
    Error_Handler();
  }
  if (HAL_UARTEx_DisableFifoMode(&huart2) != HAL_OK)
  {
    Error_Handler();
  }

}

static void MX_DMA_Init(void)
{

  /* DMA controller clock enable */
  __HAL_RCC_DMA1_CLK_ENABLE();

  /* DMA interrupt init */
  /* DMA1_Channel1_IRQn interrupt configuration */
  HAL_NVIC_SetPriority(DMA1_Channel1_IRQn, 3, 0);
  HAL_NVIC_EnableIRQ(DMA1_Channel1_IRQn);
  /* DMA1_Channel2_3_IRQn interrupt configuration */
  HAL_NVIC_SetPriority(DMA1_Channel2_3_IRQn, 3, 0);
  HAL_NVIC_EnableIRQ(DMA1_Channel2_3_IRQn);
  /* DMA1_Ch4_7_DMAMUX1_OVR_IRQn interrupt configuration */
  HAL_NVIC_SetPriority(DMA1_Ch4_7_DMAMUX1_OVR_IRQn, 3, 0);
  HAL_NVIC_EnableIRQ(DMA1_Ch4_7_DMAMUX1_OVR_IRQn);

}

static void MX_GPIO_Init(void)
{
  GPIO_InitTypeDef GPIO_InitStruct = {0};

  /* GPIO Ports Clock Enable */
  __HAL_RCC_GPIOC_CLK_ENABLE();
  __HAL_RCC_GPIOA_CLK_ENABLE();
  __HAL_RCC_GPIOB_CLK_ENABLE();
  __HAL_RCC_GPIOD_CLK_ENABLE();

  /*Configure GPIO pin Output Level */
  HAL_GPIO_WritePin(GPIOC, MOTOR_ON_Pin|AC_ON_Pin|PULSE_RST_Pin|TOP_RST_Pin
                          |SW_STATOR1_Pin|SW_STATOR2_Pin, GPIO_PIN_RESET);

  /*Configure GPIO pin Output Level */
  HAL_GPIO_WritePin(GPIOC, PULSE_ON_Pin|PAD1_ON_Pin|PAD2_ON_Pin|PTC1_ON_Pin
                          |PTC2_ON_Pin|WC_EEPROM_Pin, GPIO_PIN_SET);

  /*Configure GPIO pin Output Level */
  HAL_GPIO_WritePin(GPIOA, PTC1_FAN2_Pin|PTC2_FAN2_Pin, GPIO_PIN_SET);

  /*Configure GPIO pin Output Level */
  HAL_GPIO_WritePin(RED_LED_GPIO_Port, RED_LED_Pin, GPIO_PIN_SET);

  /*Configure GPIO pin Output Level */
  HAL_GPIO_WritePin(GPIOD, ON_CHM1_MOT_Pin|DIR_CHM1_MOT_Pin|ON_CHM2_MOT_Pin|DIR_CHM2_MOT_Pin
                          |BREAK_ON_Pin, GPIO_PIN_RESET);

  /*Configure GPIO pin : MOTOR_ON_Pin */
  GPIO_InitStruct.Pin = MOTOR_ON_Pin;
  GPIO_InitStruct.Mode = GPIO_MODE_OUTPUT_OD;
  GPIO_InitStruct.Pull = GPIO_PULLUP;
  GPIO_InitStruct.Speed = GPIO_SPEED_FREQ_LOW;
  HAL_GPIO_Init(MOTOR_ON_GPIO_Port, &GPIO_InitStruct);

  /*Configure GPIO pins : PULSE_ON_Pin PAD1_ON_Pin PAD2_ON_Pin PTC1_ON_Pin
                           PTC2_ON_Pin */
  GPIO_InitStruct.Pin = PULSE_ON_Pin|PAD1_ON_Pin|PAD2_ON_Pin|PTC1_ON_Pin
                          |PTC2_ON_Pin;
  GPIO_InitStruct.Mode = GPIO_MODE_OUTPUT_OD;
  GPIO_InitStruct.Pull = GPIO_NOPULL;
  GPIO_InitStruct.Speed = GPIO_SPEED_FREQ_LOW;
  HAL_GPIO_Init(GPIOC, &GPIO_InitStruct);

  /*Configure GPIO pins : AC_ON_Pin PULSE_RST_Pin WC_EEPROM_Pin TOP_RST_Pin
                           SW_STATOR1_Pin SW_STATOR2_Pin */
  GPIO_InitStruct.Pin = AC_ON_Pin|PULSE_RST_Pin|WC_EEPROM_Pin|TOP_RST_Pin
                          |SW_STATOR1_Pin|SW_STATOR2_Pin;
  GPIO_InitStruct.Mode = GPIO_MODE_OUTPUT_PP;
  GPIO_InitStruct.Pull = GPIO_NOPULL;
  GPIO_InitStruct.Speed = GPIO_SPEED_FREQ_LOW;
  HAL_GPIO_Init(GPIOC, &GPIO_InitStruct);

  /*Configure GPIO pins : PTC1_FAN2_Pin PTC2_FAN2_Pin */
  GPIO_InitStruct.Pin = PTC1_FAN2_Pin|PTC2_FAN2_Pin;
  GPIO_InitStruct.Mode = GPIO_MODE_OUTPUT_OD;
  GPIO_InitStruct.Pull = GPIO_NOPULL;
  GPIO_InitStruct.Speed = GPIO_SPEED_FREQ_LOW;
  HAL_GPIO_Init(GPIOA, &GPIO_InitStruct);

  /*Configure GPIO pin : S_ROTATION_Pin */
  GPIO_InitStruct.Pin = S_ROTATION_Pin;
  GPIO_InitStruct.Mode = GPIO_MODE_IT_RISING;
  GPIO_InitStruct.Pull = GPIO_NOPULL;
  HAL_GPIO_Init(S_ROTATION_GPIO_Port, &GPIO_InitStruct);

  /*Configure GPIO pin : RED_LED_Pin */
  GPIO_InitStruct.Pin = RED_LED_Pin;
  GPIO_InitStruct.Mode = GPIO_MODE_OUTPUT_OD;
  GPIO_InitStruct.Pull = GPIO_NOPULL;
  GPIO_InitStruct.Speed = GPIO_SPEED_FREQ_LOW;
  HAL_GPIO_Init(RED_LED_GPIO_Port, &GPIO_InitStruct);

  /*Configure GPIO pins : TOP_REMOVED_Pin TOP_PRESENT_Pin LID_OPEN_Pin */
  GPIO_InitStruct.Pin = TOP_REMOVED_Pin|TOP_PRESENT_Pin|LID_OPEN_Pin;
  GPIO_InitStruct.Mode = GPIO_MODE_INPUT;
  GPIO_InitStruct.Pull = GPIO_NOPULL;
  HAL_GPIO_Init(GPIOB, &GPIO_InitStruct);

  /*Configure GPIO pins : PRESENT_CHM1_Pin PRESENT_CHM2_Pin PRESENT_TANK_Pin */
  GPIO_InitStruct.Pin = PRESENT_CHM1_Pin|PRESENT_CHM2_Pin|PRESENT_TANK_Pin;
  GPIO_InitStruct.Mode = GPIO_MODE_INPUT;
  GPIO_InitStruct.Pull = GPIO_NOPULL;
  HAL_GPIO_Init(GPIOD, &GPIO_InitStruct);

  /*Configure GPIO pins : ON_CHM1_MOT_Pin DIR_CHM1_MOT_Pin ON_CHM2_MOT_Pin DIR_CHM2_MOT_Pin
                           BREAK_ON_Pin */
  GPIO_InitStruct.Pin = ON_CHM1_MOT_Pin|DIR_CHM1_MOT_Pin|ON_CHM2_MOT_Pin|DIR_CHM2_MOT_Pin
                          |BREAK_ON_Pin;
  GPIO_InitStruct.Mode = GPIO_MODE_OUTPUT_PP;
  GPIO_InitStruct.Pull = GPIO_NOPULL;
  GPIO_InitStruct.Speed = GPIO_SPEED_FREQ_LOW;
  HAL_GPIO_Init(GPIOD, &GPIO_InitStruct);

  /*Configure GPIO pins : AC_MAIN_Pin AC_MOTOR_Pin */
  GPIO_InitStruct.Pin = AC_MAIN_Pin|AC_MOTOR_Pin;
  GPIO_InitStruct.Mode = GPIO_MODE_IT_FALLING;
  GPIO_InitStruct.Pull = GPIO_NOPULL;
  HAL_GPIO_Init(GPIOB, &GPIO_InitStruct);

  /* EXTI interrupt init*/
  HAL_NVIC_SetPriority(EXTI4_15_IRQn, 3, 0);
  HAL_NVIC_EnableIRQ(EXTI4_15_IRQn);

}

void StartDefaultTask(void const * argument)
{
  for(;;)
  {
    osDelay(1);
  }
}

void Error_Handler(void)
{
  __disable_irq();
  while (1)
  {
  }
}
